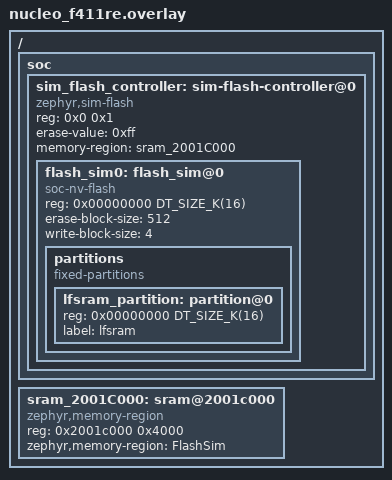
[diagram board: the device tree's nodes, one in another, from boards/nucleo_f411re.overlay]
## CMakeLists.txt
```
#
# Copyright (c) 2018 Nordic Semiconductor ASA.
#
# SPDX-License-Identifier: Apache-2.0
#

cmake_minimum_required(VERSION 3.28.0)
find_package(Zephyr REQUIRED HINTS $ENV{ZEPHYR_BASE})
project(flash_simulator)

FILE(GLOB app_sources src/*.c)
target_sources(app PRIVATE ${app_sources})
```

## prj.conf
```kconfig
CONFIG_ZTEST=y
CONFIG_FLASH=y
CONFIG_FLASH_SIMULATOR_CALLBACKS=y
CONFIG_FLASH_SIMULATOR_DOUBLE_WRITES=n
CONFIG_FLASH_SIMULATOR_UNALIGNED_READ=n
```

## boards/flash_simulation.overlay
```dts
/*
 * Copyright (c) 2024 BayLibre SAS
 *
 * SPDX-License-Identifier: Apache-2.0
 */

#include <mem.h>

/ {
	sim_flash_controller: sim_flash_controller {
		compatible = "zephyr,sim-flash";

		#address-cells = <1>;
		#size-cells = <1>;
		erase-value = <0xff>;

		flash_sim0: flash_sim@0 {
			compatible = "soc-nv-flash";
			reg = <0x00000000 DT_SIZE_M(1)>;

			erase-block-size = <1024>;
			write-block-size = <4>;
		};
	};
};
```

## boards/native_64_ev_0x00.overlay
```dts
/*
 * Copyright (c) 2020 Nordic Semiconductor ASA
 *
 * SPDX-License-Identifier: Apache-2.0
 */

#include "native_ev_0x00.overlay"
```

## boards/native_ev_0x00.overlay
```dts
/*
 * Copyright (c) 2020 Nordic Semiconductor ASA
 *
 * SPDX-License-Identifier: Apache-2.0
 */

&flashcontroller0 {
	erase-value = <0x00>;
};

&flash0 {
	reg = <0x00000000 DT_SIZE_K(1024)>;
	erase-block-size = <1024>;
	write-block-size = <4>;
};
```

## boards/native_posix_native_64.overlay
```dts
/*
 * Copyright (c) 2024 Nordic Semiconductor ASA
 *
 * SPDX-License-Identifier: Apache-2.0
 */

#include "native_posix.overlay"
```

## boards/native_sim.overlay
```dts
/*
 * Copyright (c) 2020 Jan Van Winkel <jan.van_winkel@dxplore.eu>
 *
 * SPDX-License-Identifier: Apache-2.0
 */

&flash0 {
	reg = <0x00000000 DT_SIZE_K(1024)>;
	erase-block-size = <1024>;
	write-block-size = <4>;
};
```

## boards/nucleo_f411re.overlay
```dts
/*
 * Copyright (c) 2023 Laczen
 *
 * SPDX-License-Identifier: Apache-2.0
 */

/ {
	soc {
		sim_flash_controller: sim-flash-controller@0 {
			compatible = "zephyr,sim-flash";
			reg = <0x0 0x1>;

			#address-cells = <1>;
			#size-cells = <1>;
			erase-value = <0xff>;
			memory-region = <&sram_2001C000>;

			flash_sim0: flash_sim@0 {
				compatible = "soc-nv-flash";
				reg = <0x00000000 DT_SIZE_K(16)>;
				erase-block-size = <512>;
				/* the flash_simulator test uses a write block
				 * size of 4 for alignment test, so set it to 4.
				 */
				write-block-size = <4>;
				status = "okay";
			};
		};
	};

	sram_2001C000: sram@2001c000 {
		compatible = "zephyr,memory-region", "mmio-sram";
		reg = <0x2001c000 0x4000>;
		zephyr,memory-region = "FlashSim";
		status = "okay";
	};
};

&flash_sim0 {
	partitions {
		compatible = "fixed-partitions";
		#address-cells = <1>;
		#size-cells = <1>;

		lfsram_partition: partition@0 {
			reg = <0x00000000 DT_SIZE_K(16)>;
			label = "lfsram";
		};
	};
};
```

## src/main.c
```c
/*
 * Copyright (c) 2018 Nordic Semiconductor ASA.
 *
 * SPDX-License-Identifier: Apache-2.0
 */

#include <zephyr/ztest.h>
#include <zephyr/drivers/flash.h>
#include <zephyr/device.h>
#include <zephyr/storage/flash_map.h>

/* Warning: The test has been written for testing boards with single
 * instance of Flash Simulator device only.
 */

/* configuration derived from DT */
#ifdef CONFIG_ARCH_POSIX
#define SOC_NV_FLASH_NODE DT_CHILD(DT_INST(0, zephyr_sim_flash), flash_0)
#else
#define SOC_NV_FLASH_NODE DT_CHILD(DT_INST(0, zephyr_sim_flash), flash_sim_0)
#endif /* CONFIG_ARCH_POSIX */
#define FLASH_SIMULATOR_BASE_OFFSET PARTITION_NODE_OFFSET(SOC_NV_FLASH_NODE)
#define FLASH_SIMULATOR_ERASE_UNIT DT_PROP(SOC_NV_FLASH_NODE, erase_block_size)
#define FLASH_SIMULATOR_PROG_UNIT DT_PROP(SOC_NV_FLASH_NODE, write_block_size)
#define FLASH_SIMULATOR_FLASH_SIZE DT_REG_SIZE(SOC_NV_FLASH_NODE)

#define FLASH_SIMULATOR_ERASE_VALUE \
		DT_PROP(DT_PARENT(SOC_NV_FLASH_NODE), erase_value)

/* Offset between pages */
#define TEST_SIM_FLASH_SIZE FLASH_SIMULATOR_FLASH_SIZE

#define TEST_SIM_FLASH_END (TEST_SIM_FLASH_SIZE +\
			   FLASH_SIMULATOR_BASE_OFFSET)

#define PATTERN8TO32BIT(pat) \
		(((((((0xff & pat) << 8) | (0xff & pat)) << 8) | \
		   (0xff & pat)) << 8) | (0xff & pat))

#if (defined(CONFIG_ARCH_POSIX) || defined(CONFIG_BOARD_QEMU_X86))
static const struct device *const flash_dev = DEVICE_DT_GET(DT_CHOSEN(zephyr_flash_controller));
#else
static const struct device *const flash_dev = DEVICE_DT_GET(DT_NODELABEL(sim_flash_controller));
#endif
static uint8_t test_read_buf[TEST_SIM_FLASH_SIZE];

static uint32_t p32_inc;

void pattern32_ini(uint32_t val)
{
	p32_inc = val;
}

static uint32_t pattern32_inc(void)
{
	return p32_inc++;
}

static uint32_t pattern32_flat(void)
{
	return p32_inc;
}

static void test_check_pattern32(off_t start, uint32_t (*pattern_gen)(void),
				 size_t size)
{
	off_t off;
	uint32_t val32, r_val32;
	int rc;

	for (off = 0; off < size; off += 4) {
		rc = flash_read(flash_dev, start + off, &r_val32,
				sizeof(r_val32));
		zassert_equal(0, rc, "flash_write should succeed");
		val32 = pattern_gen();
		zassert_equal(val32, r_val32,
			     "flash word at offset 0x%x has value 0x%08x, " \
			     "expected 0x%08x",
			     (uint32_t)(start + off), r_val32, val32);
	}
}

/* ret < 0 is errno; ret == 1 is bad value in flash */
static int test_check_erase(const struct device *dev, off_t offset, size_t size)
{
	uint8_t buf[FLASH_SIMULATOR_PROG_UNIT];
	int rc;
	int i = 0;

	BUILD_ASSERT(sizeof(buf) >= FLASH_SIMULATOR_PROG_UNIT);

	i = 0;
	while (i < size) {
		size_t chunk = MIN(size - i, sizeof(buf));
		/* The memset is done to set buf to something else than
		 * FLASH_SIMULATOR_ERASE_VALUE, as we are trying to check
		 * whether that is what is now in the memory.
		 */
		memset(buf, ~FLASH_SIMULATOR_ERASE_VALUE, sizeof(buf));
		rc = flash_read(flash_dev, offset + i,
				buf, chunk);
		if (rc < 0) {
			TC_PRINT("Unexpected flash_read fail @ %ld",
				 (long)(offset + i));
			return rc;
		}
		do {
			if ((uint8_t)buf[i & (sizeof(buf) - 1)] !=
			    (uint8_t)FLASH_SIMULATOR_ERASE_VALUE) {
				TC_PRINT("Flash not erased at %ld\n",
					 (long)(offset + i));
				return 1;
			}
			++i;
			--chunk;
		} while (chunk);
	}
	return 0;
}

/* Get access to the device and erase it ready for testing*/
static void test_init(void)
{
	zassert_true(device_is_ready(flash_dev),
		     "Simulated flash device not ready");
}

ZTEST(flash_sim_api, test_read)
{
	off_t i;
	int rc;

	rc = flash_erase(flash_dev, FLASH_SIMULATOR_BASE_OFFSET,
			 FLASH_SIMULATOR_FLASH_SIZE);
	zassert_equal(0, rc, "flash_erase should succeed");


	rc = flash_read(flash_dev, FLASH_SIMULATOR_BASE_OFFSET,
			test_read_buf, sizeof(test_read_buf));
	zassert_equal(0, rc, "flash_read should succeed");

	for (i = 0; i < sizeof(test_read_buf); i++) {
		zassert_equal(FLASH_SIMULATOR_ERASE_VALUE,
			     test_read_buf[i],
			     "sim flash byte at offset 0x%x has value 0x%08x",
			     (int)i, test_read_buf[i]);
	}
}

static void test_write_read(void)
{
	off_t off;
	uint32_t val32 = 0, r_val32;
	int rc;

	rc = flash_erase(flash_dev, FLASH_SIMULATOR_BASE_OFFSET,
			 FLASH_SIMULATOR_FLASH_SIZE);
	zassert_equal(0, rc, "flash_erase should succeed");


	for (off = 0; off < TEST_SIM_FLASH_SIZE; off += 4) {
		rc = flash_write(flash_dev, FLASH_SIMULATOR_BASE_OFFSET +
					    off,
				 &val32, sizeof(val32));
		zassert_equal(0, rc,
			      "flash_write (%d) should succeed at off 0x%x", rc,
			       FLASH_SIMULATOR_BASE_OFFSET + (int)off);
		val32++;
	}

	val32 = 0;

	for (off = 0; off < TEST_SIM_FLASH_SIZE; off += 4) {
		rc = flash_read(flash_dev, FLASH_SIMULATOR_BASE_OFFSET +
					   off,
				&r_val32, sizeof(r_val32));
		zassert_equal(0, rc, "flash_write should succeed");
		zassert_equal(val32, r_val32,
			"flash byte at offset 0x%x has value 0x%08x, expected" \
			" 0x%08x",
			(int)off, r_val32, val32);
		val32++;
	}
}

static void test_erase(void)
{
	int rc;

	rc = flash_erase(flash_dev, FLASH_SIMULATOR_BASE_OFFSET +
			 FLASH_SIMULATOR_ERASE_UNIT,
			 FLASH_SIMULATOR_ERASE_UNIT);
	zassert_equal(0, rc, "flash_erase should succeed");

	TC_PRINT("Incremental pattern expected\n");
	pattern32_ini(0);
	test_check_pattern32(FLASH_SIMULATOR_BASE_OFFSET, pattern32_inc,
			     FLASH_SIMULATOR_ERASE_UNIT);

	TC_PRINT("Erased area expected\n");
	pattern32_ini(PATTERN8TO32BIT(FLASH_SIMULATOR_ERASE_VALUE));
	test_check_pattern32(FLASH_SIMULATOR_BASE_OFFSET +
			     FLASH_SIMULATOR_ERASE_UNIT, pattern32_flat,
			     FLASH_SIMULATOR_ERASE_UNIT);

	TC_PRINT("Incremental pattern expected\n");
	pattern32_ini(FLASH_SIMULATOR_ERASE_UNIT*2 /
		      FLASH_SIMULATOR_PROG_UNIT);
	test_check_pattern32(FLASH_SIMULATOR_BASE_OFFSET +
			     FLASH_SIMULATOR_ERASE_UNIT*2, pattern32_inc,
			     FLASH_SIMULATOR_ERASE_UNIT*2);
}

ZTEST(flash_sim_api, test_write_read_erase)
{
	test_write_read();
	test_erase();
}


ZTEST(flash_sim_api, test_out_of_bounds)
{
	int rc;
	uint8_t data[8] = {0};

	rc = flash_write(flash_dev, FLASH_SIMULATOR_BASE_OFFSET - 4,
				 data, 4);
	zassert_equal(-EINVAL, rc, "Unexpected error code (%d)", rc);

	rc = flash_write(flash_dev, FLASH_SIMULATOR_BASE_OFFSET - 4,
				 data, 8);
	zassert_equal(-EINVAL, rc, "Unexpected error code (%d)", rc);

	rc = flash_write(flash_dev, TEST_SIM_FLASH_END,
				 data, 4);
	zassert_equal(-EINVAL, rc, "Unexpected error code (%d)", rc);

	rc = flash_write(flash_dev, TEST_SIM_FLASH_END - 4,
				 data, 8);
	zassert_equal(-EINVAL, rc, "Unexpected error code (%d)", rc);

	rc = flash_erase(flash_dev, FLASH_SIMULATOR_BASE_OFFSET -
			 FLASH_SIMULATOR_ERASE_UNIT,
			 FLASH_SIMULATOR_ERASE_UNIT);
	zassert_equal(-EINVAL, rc, "Unexpected error code (%d)", rc);

	rc = flash_erase(flash_dev, TEST_SIM_FLASH_END,
			 FLASH_SIMULATOR_ERASE_UNIT);
	zassert_equal(-EINVAL, rc, "Unexpected error code (%d)", rc);

	rc = flash_erase(flash_dev, FLASH_SIMULATOR_BASE_OFFSET -
			 FLASH_SIMULATOR_ERASE_UNIT*2,
			 FLASH_SIMULATOR_ERASE_UNIT*2);
	zassert_equal(-EINVAL, rc, "Unexpected error code (%d)", rc);

	rc = flash_erase(flash_dev, TEST_SIM_FLASH_END -
			 FLASH_SIMULATOR_ERASE_UNIT,
			 FLASH_SIMULATOR_ERASE_UNIT*2);
	zassert_equal(-EINVAL, rc, "Unexpected error code (%d)", rc);

	rc = flash_read(flash_dev, FLASH_SIMULATOR_BASE_OFFSET - 4,
				 data, 4);
	zassert_equal(-EINVAL, rc, "Unexpected error code (%d)", rc);

	rc = flash_read(flash_dev, FLASH_SIMULATOR_BASE_OFFSET - 4,
				 data, 8);
	zassert_equal(-EINVAL, rc, "Unexpected error code (%d)", rc);

	rc = flash_read(flash_dev, TEST_SIM_FLASH_END,
				 data, 4);
	zassert_equal(-EINVAL, rc, "Unexpected error code (%d)", rc);

	rc = flash_read(flash_dev, TEST_SIM_FLASH_END - 4, data, 8);
	zassert_equal(-EINVAL, rc, "Unexpected error code (%d)", rc);
}

ZTEST(flash_sim_api, test_align)
{
	int rc;
	uint8_t data[4] = {0};

	rc = flash_read(flash_dev, FLASH_SIMULATOR_BASE_OFFSET + 1,
				 data, 4);
	zassert_equal(-EINVAL, rc, "Unexpected error code (%d)", rc);

	rc = flash_write(flash_dev, FLASH_SIMULATOR_BASE_OFFSET + 1,
				 data, 4);
	zassert_equal(-EINVAL, rc, "Unexpected error code (%d)", rc);

	rc = flash_write(flash_dev, FLASH_SIMULATOR_BASE_OFFSET,
				 data, 3);
	zassert_equal(-EINVAL, rc, "Unexpected error code (%d)", rc);

	rc = flash_erase(flash_dev, FLASH_SIMULATOR_BASE_OFFSET + 1,
			 FLASH_SIMULATOR_ERASE_UNIT);

	zassert_equal(-EINVAL, rc, "Unexpected error code (%d)", rc);

	rc = flash_erase(flash_dev, FLASH_SIMULATOR_BASE_OFFSET,
			 FLASH_SIMULATOR_ERASE_UNIT + 1);

	zassert_equal(-EINVAL, rc, "Unexpected error code (%d)", rc);
}

ZTEST(flash_sim_api, test_double_write)
{
#if defined(CONFIG_FLASH_SIMULATOR_DOUBLE_WRITES) &&	\
	defined(CONFIG_FLASH_SIMULATOR_EXPLICIT_ERASE)
	int rc;
	/* Test checks behaviour of write when attempting to double write
	 * selected offset. Simulator, prior to write, checks if selected
	 * memory contains erased values and returns -EIO if not; data has
	 * to be initialized to value that will not be equal to erase
	 * value of flash, for this test.
	 */
	uint32_t data = ~(PATTERN8TO32BIT(FLASH_SIMULATOR_ERASE_VALUE));

	rc = flash_erase(flash_dev, FLASH_SIMULATOR_BASE_OFFSET,
			 FLASH_SIMULATOR_ERASE_UNIT);
	zassert_equal(0, rc, "flash_erase should succeed");

	rc = flash_write(flash_dev, FLASH_SIMULATOR_BASE_OFFSET,
				 &data, sizeof(data));
	zassert_equal(0, rc, "flash_write should succeed");

	rc = flash_write(flash_dev, FLASH_SIMULATOR_BASE_OFFSET,
				 &data, sizeof(data));
	zassert_equal(-EIO, rc, "Unexpected error code (%d)", rc);
#else
	ztest_test_skip();
#endif
}

ZTEST(flash_sim_api, test_ramlike)
{
#if defined(CONFIG_FLASH_SIMULATOR_RAMLIKE)
	/* Within code below there is assumption that the src size is
	 * equal or greater than the FLASH_SIMULATOR_PROG_UNIT
	 * (write-block-size) of device.
	 */
	const uint8_t src[] = "Hello world! This is test string";
	uint8_t buf[FLASH_SIMULATOR_PROG_UNIT];
	/* Round up to next write-block-size */
	int max = (sizeof(src) + FLASH_SIMULATOR_PROG_UNIT - 1) &
		  ~(FLASH_SIMULATOR_PROG_UNIT - 1);
	int rc;
	int i = 0;
	int is = 0;	/* The index within src */

	BUILD_ASSERT(sizeof(src) >= FLASH_SIMULATOR_PROG_UNIT);

	/* Scrub memory with something constant */
	memset(buf, FLASH_SIMULATOR_ERASE_VALUE, sizeof(buf));
	while (i < max) {
		rc = flash_write(flash_dev, FLASH_SIMULATOR_BASE_OFFSET + i,
				 buf, sizeof(buf));
		zassert_equal(0, rc, "flash_write should succeed");
		i += sizeof(buf);
	}

	/* Check the scrubbing */
	zassert_equal(0, test_check_erase(flash_dev, FLASH_SIMULATOR_BASE_OFFSET, max),
		      "Area not erased");

	/* Now write something new */
	i = 0;
	while (i < max) {
		do {
			buf[i & (sizeof(buf) - 1)] = src[is];
			++i;
			++is;

			/* Continue writing from the beginning of the src */
			if (is >= sizeof(src)) {
				is = 0;
			}
		} while (i & (sizeof(buf) - 1));
		rc = flash_write(flash_dev, FLASH_SIMULATOR_BASE_OFFSET	+ i - sizeof(buf),
				 buf, sizeof(buf));
		zassert_equal(0, rc, "flash_write should succeed");
	}

	/* Check the write */
	i = 0;
	is = 0;
	while (i < max) {
		rc = flash_read(flash_dev, FLASH_SIMULATOR_BASE_OFFSET + i,
				buf, sizeof(buf));
		zassert_equal(0, rc, "flash_read should succeed");
		do {
			zassert_equal((uint8_t)src[is], (uint8_t)buf[i & (sizeof(buf) - 1)],
				      "Expected src and buf to match at index %d\n", i);
			++i;
			++is;
			/* Src has wrapped around */
			if (is >= sizeof(src)) {
				is = 0;
			}
		} while (i & (sizeof(buf) - 1));
		zassert_equal(0, rc, "Unexpected value read");
	}

	/* Because we are checking random access writes, we are now going to
	 * write binary not of the same data we have just written. If this would be
	 * program-erase type memory, where you can only change from erase value
	 * to opposite, such write would render incorrect data in memory,
	 * but this is random access device so we should get exactly what we write.
	 */
	i = 0;
	is = 0;
	while (i < max) {
		do {
			buf[i & (sizeof(buf) - 1)] = ~src[is];
			++i;
			++is;

			/* Continue writing from the beginning of the src */
			if (is >= sizeof(src)) {
				is = 0;
			}
		} while (i & (sizeof(buf) - 1));
		rc = flash_write(flash_dev, FLASH_SIMULATOR_BASE_OFFSET	+ i - sizeof(buf),
				 buf, sizeof(buf));
		zassert_equal(0, rc, "flash_write should succeed");
	}

	/* Check the write */
	i = 0;
	is = 0;
	while (i < max) {
		rc = flash_read(flash_dev, FLASH_SIMULATOR_BASE_OFFSET + i,
				buf, sizeof(buf));
		zassert_equal(0, rc, "flash_read should succeed");
		do {
			zassert_equal((uint8_t)~src[is], (uint8_t)buf[i & (sizeof(buf) - 1)],
				      "Expected src and buf to match at index %d\n", i);
			++i;
			++is;
			/* Src has wrapped around */
			if (is >= sizeof(src)) {
				is = 0;
			}
		} while (i & (sizeof(buf) - 1));
		zassert_equal(0, rc, "Unexpected value read");
	}
#else
	ztest_test_skip();
#endif
}

ZTEST(flash_sim_api, test_get_erase_value)
{
	const struct flash_parameters *fp = flash_get_parameters(flash_dev);

	zassert_equal(fp->erase_value, FLASH_SIMULATOR_ERASE_VALUE,
		      "Expected erase value %x",
		      FLASH_SIMULATOR_ERASE_VALUE);
}

ZTEST(flash_sim_api, test_erase_capability)
{
	/* Verify that the runtime device capability matches the build configuration.
	 * This is the test that was missing and resulted in issue #100352 not being caught:
	 * the driver was incorrectly setting no_explicit_erase for all instances based
	 * on a global Kconfig rather than per-instance properties.
	 */
	const struct flash_parameters *fp = flash_get_parameters(flash_dev);
	int erase_cap;

	zassert_not_null(fp, "flash_get_parameters() returned NULL");

	erase_cap = flash_params_get_erase_cap(fp);

#if defined(CONFIG_FLASH_SIMULATOR_EXPLICIT_ERASE)
	/* Erase-type (classic Flash) device: must report explicit erase required */
	zassert_false(fp->caps.no_explicit_erase,
		      "Device is configured as explicit-erase but caps.no_explicit_erase=true");
	zassert_equal(FLASH_ERASE_C_EXPLICIT, erase_cap,
		      "Expected FLASH_ERASE_C_EXPLICIT (0x%x), got 0x%x",
		      FLASH_ERASE_C_EXPLICIT, erase_cap);
#else
	/* RAM-like device: must report no explicit erase required */
	zassert_true(fp->caps.no_explicit_erase,
		     "Device is configured as RAM-like but caps.no_explicit_erase=false");
	zassert_equal(0, erase_cap,
		      "Expected erase capability 0 for RAM-like device, got 0x%x", erase_cap);
#endif
}

ZTEST(flash_sim_api, test_flash_fill)
{
	off_t i;
	int rc;
	uint8_t buf[FLASH_SIMULATOR_PROG_UNIT];
#if defined(CONFIG_FLASH_SIMULATOR_EXPLICIT_ERASE)
	rc = flash_erase(flash_dev, FLASH_SIMULATOR_BASE_OFFSET,
			 FLASH_SIMULATOR_FLASH_SIZE);
	zassert_equal(0, rc, "flash_erase should succeed");
#else
	rc = flash_fill(flash_dev, FLASH_SIMULATOR_ERASE_VALUE,
			FLASH_SIMULATOR_BASE_OFFSET,
			FLASH_SIMULATOR_FLASH_SIZE);
	zassert_equal(0, rc, "flash_fill should succeed");
#endif
	size_t size = FLASH_SIMULATOR_FLASH_SIZE;

	zassert_equal(0, test_check_erase(flash_dev, FLASH_SIMULATOR_BASE_OFFSET,
					  FLASH_SIMULATOR_FLASH_SIZE),
		      "Area not erased");

	rc = flash_fill(flash_dev, 0x55,
			FLASH_SIMULATOR_BASE_OFFSET,
			FLASH_SIMULATOR_FLASH_SIZE);
	zassert_equal(0, rc, "flash_fill should succeed");

	/* Check if fill did work on both type of devices */
	i = 0;
	size = FLASH_SIMULATOR_FLASH_SIZE;
	while (i < FLASH_SIMULATOR_FLASH_SIZE) {
		size_t chunk = MIN(size, FLASH_SIMULATOR_PROG_UNIT);

		memset(buf, FLASH_SIMULATOR_ERASE_VALUE, sizeof(buf));
		rc = flash_read(flash_dev, FLASH_SIMULATOR_BASE_OFFSET + i,
				buf, chunk);
		zassert_equal(0, rc, "flash_read should succeed at offset %d", (int)i);
		do {
			zassert_equal((uint8_t)buf[i & (sizeof(buf) - 1)], 0x55,
				      "Unexpected value at offset %d\n", (int)i);
			++i;
			--size;
			--chunk;
		} while (chunk);
	}
}

#if !defined(CONFIG_FLASH_SIMULATOR_EXPLICIT_ERASE)
/* Forwarding flash API instance with erase intentionally set to NULL, used by
 * test_flash_flatten to verify the flash_flatten() fallback to flash_fill()
 * when the driver's erase callback is unimplemented. The instance must live
 * in the flash driver API iterable section (declared via DEVICE_API) so that
 * DEVICE_API_GET passes its class assertion at runtime.
 */
static int no_erase_api_read(const struct device *dev, off_t offset, void *data, size_t len)
{
	ARG_UNUSED(dev);
	return flash_read(flash_dev, offset, data, len);
}

static int no_erase_api_write(const struct device *dev, off_t offset, const void *data,
			      size_t len)
{
	ARG_UNUSED(dev);
	return flash_write(flash_dev, offset, data, len);
}

static const struct flash_parameters *no_erase_api_get_parameters(const struct device *dev)
{
	ARG_UNUSED(dev);
	return flash_get_parameters(flash_dev);
}

static DEVICE_API(flash, no_erase_api) = {
	.read = no_erase_api_read,
	.write = no_erase_api_write,
	.erase = NULL,
	.get_parameters = no_erase_api_get_parameters,
};
#endif

ZTEST(flash_sim_api, test_flash_flatten)
{
	int rc;
#if defined(CONFIG_FLASH_SIMULATOR_EXPLICIT_ERASE)
	rc = flash_erase(flash_dev, FLASH_SIMULATOR_BASE_OFFSET,
			 FLASH_SIMULATOR_FLASH_SIZE);
	zassert_equal(0, rc, "flash_erase should succeed");
#else
	rc = flash_fill(flash_dev, FLASH_SIMULATOR_ERASE_VALUE,
			FLASH_SIMULATOR_BASE_OFFSET,
			FLASH_SIMULATOR_FLASH_SIZE);
	zassert_equal(0, rc, "flash_fill should succeed");
#endif
	/* Now fill the device with anything */
	rc = flash_fill(flash_dev, 0xaa,
			FLASH_SIMULATOR_BASE_OFFSET,
			FLASH_SIMULATOR_FLASH_SIZE);
	zassert_equal(0, rc, "flash_fill should succeed");

	/* And erase */
	rc = flash_flatten(flash_dev, FLASH_SIMULATOR_BASE_OFFSET,
			   FLASH_SIMULATOR_FLASH_SIZE);
	zassert_equal(0, rc, "flash_flatten should succeed");

#if !defined(CONFIG_FLASH_SIMULATOR_EXPLICIT_ERASE)
	/* In case of RAM like devices, the erase may not be
	 * provided, in such case flash_flatten calls flash_fill
	 * with erase_value.
	 */
	struct device other;

	memcpy(&other, flash_dev, sizeof(other));
	other.api = &no_erase_api;

	/* Now fill the device with anything */
	rc = flash_fill(flash_dev, 0xaa,
			FLASH_SIMULATOR_BASE_OFFSET,
			FLASH_SIMULATOR_FLASH_SIZE);
	zassert_equal(0, rc, "flash_fill should succeed");

	/* The erase is not implemented */
	rc = flash_erase(&other, FLASH_SIMULATOR_BASE_OFFSET,
			 FLASH_SIMULATOR_FLASH_SIZE);
	zassert_equal(-ENOSYS, rc, "Expected not implemented");

	rc = flash_flatten(&other, FLASH_SIMULATOR_BASE_OFFSET,
				  FLASH_SIMULATOR_FLASH_SIZE);
	zassert_equal(0, rc, "flash_flatten should succeed");

	test_check_erase(flash_dev, FLASH_SIMULATOR_BASE_OFFSET,
			 FLASH_SIMULATOR_FLASH_SIZE);

#endif
}

#include <zephyr/drivers/flash/flash_simulator.h>

ZTEST(flash_sim_api, test_get_mock)
{
#ifdef CONFIG_ARCH_POSIX
	ztest_test_skip();
#else
	size_t mock_size;
	void *mock_ptr;

	mock_ptr = flash_simulator_get_memory(flash_dev, &mock_size);

	zassert_true(mock_ptr != NULL,
		     "Expected mock_flash address, got NULL.");
	zassert_equal(mock_size, FLASH_SIMULATOR_FLASH_SIZE,
		     "Expected mock_flash size %d, got %d",
		      FLASH_SIMULATOR_FLASH_SIZE, mock_size);
#endif
}

void *flash_sim_setup(void)
{
	test_init();

	return NULL;
}

ZTEST_SUITE(flash_sim_api, NULL, flash_sim_setup, NULL, NULL, NULL);
```

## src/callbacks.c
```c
/*
 * Copyright (c) 2025 Koppel Electronic
 *
 * SPDX-License-Identifier: Apache-2.0
 */
#include <stdlib.h>
#include <zephyr/ztest.h>
#include <zephyr/drivers/flash.h>
#include <zephyr/drivers/flash/flash_simulator.h>
#include <zephyr/device.h>

/* Test the flash simulator callbacks to modify the behaviour of the
 * flash simulator on the fly.
 */

/* configuration derived from DT */
#ifdef CONFIG_ARCH_POSIX
#define SOC_NV_FLASH_NODE DT_CHILD(DT_INST(0, zephyr_sim_flash), flash_0)
#else
#define SOC_NV_FLASH_NODE DT_CHILD(DT_INST(0, zephyr_sim_flash), flash_sim_0)
#endif /* CONFIG_ARCH_POSIX */
#define FLASH_SIMULATOR_BASE_OFFSET DT_REG_ADDR(SOC_NV_FLASH_NODE)
#define FLASH_SIMULATOR_ERASE_UNIT DT_PROP(SOC_NV_FLASH_NODE, erase_block_size)
#define FLASH_SIMULATOR_PROG_UNIT DT_PROP(SOC_NV_FLASH_NODE, write_block_size)
#define FLASH_SIMULATOR_FLASH_SIZE DT_REG_SIZE(SOC_NV_FLASH_NODE)

#define FLASH_SIMULATOR_ERASE_VALUE \
		DT_PROP(DT_PARENT(SOC_NV_FLASH_NODE), erase_value)

#if (defined(CONFIG_ARCH_POSIX) || defined(CONFIG_BOARD_QEMU_X86))
static const struct device *const flash_dev = DEVICE_DT_GET(DT_CHOSEN(zephyr_flash_controller));
#else
static const struct device *const flash_dev = DEVICE_DT_GET(DT_NODELABEL(sim_flash_controller));
#endif


/* We are simulating the broken FLASH memory.
 * Simulate different types of errors depending on the erase page.
 * Page 0: behaves normal
 * Page 1: erase works as expected, all writes fails (no write, -EIO returned)
 * Page 2: erase works as expected, all writes silently corrupt data (bits 0, 1, 20 in sticks to 1)
 * Page 3: erase fails (no erase, -EIO returned), all writes fails (-EIO returned)
 * Page 4: erase fails silently (erases writes 0x55 to all bytes), all writes fails (-EIO returned)
 */
enum test_page_type {
	TEST_PAGE_TYPE_NORMAL,
	TEST_PAGE_TYPE_ERASE_OK_WRITE_FAIL,
	TEST_PAGE_TYPE_ERASE_OK_WRITE_CORRUPT,
	TEST_PAGE_TYPE_ERASE_FAIL_WRITE_FAIL,
	TEST_PAGE_TYPE_ERASE_CORRUPT_WRITE_FAIL,
};

/* Corruption pattern for write operations: bits 0, 1, and 20 in 32-bit word */
static const uint32_t test_write_corruption_pattern = 0x00100003;

static int test_write_byte_callback(const struct device *dev, off_t offset, uint8_t data)
{
	const struct flash_simulator_params *params = flash_simulator_get_params(dev);
	enum test_page_type page = offset / params->erase_unit;

	switch (page) {
	case TEST_PAGE_TYPE_ERASE_OK_WRITE_FAIL:
	case TEST_PAGE_TYPE_ERASE_FAIL_WRITE_FAIL:
	case TEST_PAGE_TYPE_ERASE_CORRUPT_WRITE_FAIL:
		return -EIO;
	case TEST_PAGE_TYPE_ERASE_OK_WRITE_CORRUPT: {
		/* Apply corruption pattern based on byte position within word */
		uint8_t byte_in_word = offset & 0x3;
		uint8_t corruption_byte =
			(test_write_corruption_pattern >> (byte_in_word * 8)) & 0xFF;

		return data | corruption_byte;
	}
	case TEST_PAGE_TYPE_NORMAL:
	default:
		return data;
	}
}

static int test_erase_unit_callback(const struct device *dev, off_t offset)
{
	const struct flash_simulator_params *params = flash_simulator_get_params(dev);
	enum test_page_type page = offset / params->erase_unit;
	size_t flash_size;
	uint8_t *flash_mock = flash_simulator_get_memory(dev, &flash_size);

	zassert_true(offset < flash_size, "Offset 0x%lx out of range (flash size 0x%zx)",
		    (long)offset, flash_size);

	switch (page) {
	case TEST_PAGE_TYPE_ERASE_FAIL_WRITE_FAIL:
		return -EIO;
	case TEST_PAGE_TYPE_ERASE_CORRUPT_WRITE_FAIL:
		/* Corrupt erase by writing 0x55 to all bytes */
		memset(flash_mock + offset, 0x55, params->erase_unit);
		return 0;
	case TEST_PAGE_TYPE_NORMAL:
	case TEST_PAGE_TYPE_ERASE_OK_WRITE_FAIL:
	case TEST_PAGE_TYPE_ERASE_OK_WRITE_CORRUPT:
	default:
		/* Normal erase behavior - callback must perform the erase */
		memset(flash_mock + offset, params->erase_value, params->erase_unit);
		return 0;
	}
}

static struct flash_simulator_cb test_flash_sim_cbs = {
	.write_byte = test_write_byte_callback,
	.erase_unit = test_erase_unit_callback,
};

void *flash_sim_cbs_setup(void)
{
	zassert_true(device_is_ready(flash_dev),
		     "Simulated flash device not ready");

	flash_simulator_set_callbacks(flash_dev, &test_flash_sim_cbs);

	return NULL;
}

/* Disable callbacks after tests to restore default simulator behavior */
static void flash_sim_cbs_teardown(void *fixture)
{
	ARG_UNUSED(fixture);
	flash_simulator_set_callbacks(flash_dev, NULL);
}

ZTEST(flash_sim_cbs, test_page_behaviors)
{
	int ret;
	uint32_t write_buf[FLASH_SIMULATOR_ERASE_UNIT / sizeof(uint32_t)];
	uint32_t read_buf[FLASH_SIMULATOR_ERASE_UNIT / sizeof(uint32_t)];
	off_t page_offset;
	size_t buf_size = sizeof(write_buf);

	/* Initialize write buffer with pseudo-random pattern */
	srand(0x12345678);
	for (size_t i = 0; i < ARRAY_SIZE(write_buf); i++) {
		write_buf[i] = ((uint32_t)rand() << 16) | (uint32_t)rand();
	}

	/* Test Page 0: TEST_PAGE_TYPE_NORMAL - behaves normal */
	page_offset = TEST_PAGE_TYPE_NORMAL * FLASH_SIMULATOR_ERASE_UNIT;

	ret = flash_erase(flash_dev, page_offset, FLASH_SIMULATOR_ERASE_UNIT);
	zassert_equal(ret, 0, "Page 0: Erase should succeed");

	ret = flash_write(flash_dev, page_offset, write_buf, buf_size);
	zassert_equal(ret, 0, "Page 0: Write should succeed");

	ret = flash_read(flash_dev, page_offset, read_buf, buf_size);
	zassert_equal(ret, 0, "Page 0: Read should succeed");
	zassert_mem_equal(read_buf, write_buf, buf_size,
			  "Page 0: Data should match written data");

	/* Test Page 1: TEST_PAGE_TYPE_ERASE_OK_WRITE_FAIL - erase OK, write fails */
	page_offset = TEST_PAGE_TYPE_ERASE_OK_WRITE_FAIL * FLASH_SIMULATOR_ERASE_UNIT;

	ret = flash_erase(flash_dev, page_offset, FLASH_SIMULATOR_ERASE_UNIT);
	zassert_equal(ret, 0, "Page 1: Erase should succeed");

	ret = flash_read(flash_dev, page_offset, read_buf, buf_size);
	zassert_equal(ret, 0, "Page 1: Read after erase should succeed");
	for (size_t i = 0; i < ARRAY_SIZE(read_buf); i++) {
		uint32_t expected = FLASH_SIMULATOR_ERASE_VALUE;

		expected |= (expected << 8) | (expected << 16) | (expected << 24);
		zassert_equal(read_buf[i], expected,
			      "Page 1: After erase, data should be erase value");
	}

	ret = flash_write(flash_dev, page_offset, write_buf, buf_size);
	zassert_equal(ret, -EIO, "Page 1: Write should fail with -EIO");

	/* Test Page 2: TEST_PAGE_TYPE_ERASE_OK_WRITE_CORRUPT - erase OK, write corrupts */
	page_offset = TEST_PAGE_TYPE_ERASE_OK_WRITE_CORRUPT * FLASH_SIMULATOR_ERASE_UNIT;

	ret = flash_erase(flash_dev, page_offset, FLASH_SIMULATOR_ERASE_UNIT);
	zassert_equal(ret, 0, "Page 2: Erase should succeed");

	ret = flash_write(flash_dev, page_offset, write_buf, buf_size);
	zassert_equal(ret, 0, "Page 2: Write should succeed (but corrupt data)");

	ret = flash_read(flash_dev, page_offset, read_buf, buf_size);
	zassert_equal(ret, 0, "Page 2: Read should succeed");

	/* Verify corruption pattern: bits 0, 1, and 20 should be set */
	for (size_t i = 0; i < ARRAY_SIZE(read_buf); i++) {
		uint32_t expected = write_buf[i] | test_write_corruption_pattern;

		zassert_equal(read_buf[i], expected,
			      "Page 2: Data should be corrupted with pattern 0x%08x",
			      test_write_corruption_pattern);
	}

	/* Test Page 3: TEST_PAGE_TYPE_ERASE_FAIL_WRITE_FAIL - both fail */
	page_offset = TEST_PAGE_TYPE_ERASE_FAIL_WRITE_FAIL * FLASH_SIMULATOR_ERASE_UNIT;

	ret = flash_erase(flash_dev, page_offset, FLASH_SIMULATOR_ERASE_UNIT);
	zassert_equal(ret, -EIO, "Page 3: Erase should fail with -EIO");

	ret = flash_write(flash_dev, page_offset, write_buf, buf_size);
	zassert_equal(ret, -EIO, "Page 3: Write should fail with -EIO");

	/* Test Page 4: TEST_PAGE_TYPE_ERASE_CORRUPT_WRITE_FAIL - erase corrupts, write fails */
	page_offset = TEST_PAGE_TYPE_ERASE_CORRUPT_WRITE_FAIL * FLASH_SIMULATOR_ERASE_UNIT;

	ret = flash_erase(flash_dev, page_offset, FLASH_SIMULATOR_ERASE_UNIT);
	zassert_equal(ret, 0, "Page 4: Erase should succeed (but corrupt)");

	ret = flash_read(flash_dev, page_offset, read_buf, buf_size);
	zassert_equal(ret, 0, "Page 4: Read after erase should succeed");
	for (size_t i = 0; i < ARRAY_SIZE(read_buf); i++) {
		zassert_equal(read_buf[i], 0x55555555,
			      "Page 4: After erase, data should be 0x55555555 (corrupted erase)");
	}

	ret = flash_write(flash_dev, page_offset, write_buf, buf_size);
	zassert_equal(ret, -EIO, "Page 4: Write should fail with -EIO");
}

ZTEST_SUITE(flash_sim_cbs, NULL, flash_sim_cbs_setup, NULL, NULL, flash_sim_cbs_teardown);
```
